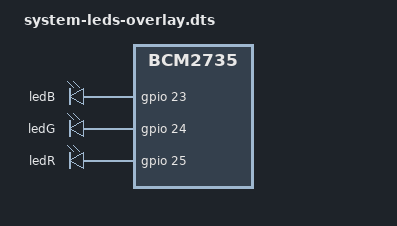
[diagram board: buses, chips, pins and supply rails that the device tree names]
/dts-v1/;
/plugin/;

/ {

  compatible = "brcm,bcm2735";

	fragment@0 {
		target = <&gpio>;
		__overlay__ {
			system_leds_pins: system_leds_pins {
			  brcm,pins = <23 24 25>;
			  brcm,function = <1 1 1>; // 0 = input, 1 = output
			  brcm,pull = <0 0 0>; // 0 = none, 1 = pull down, 2 = pull up
		  };
	  };
  };

	fragment@1 {
		target-path = "/";
		__overlay__ {
			system_leds: system_leds {
			  compatible = "gpio-leds";
			  pinctrl-names = "default";
			  pinctrl-0 = <&system_leds_pins>;
			  status = "okay";

			  ledR: ledR {
		      label = "ledB";
					gpios = <&gpio 23 0>;
			    linux,default-trigger = "none";
				};

        ledG: ledG {
		      label = "ledG";
					gpios = <&gpio 24 0>;
			    linux,default-trigger = "none";
				};

        ledB: ledB {
		      label = "ledR";
				  gpios = <&gpio 25 0>;
			    linux,default-trigger = "none";
				};
			};
		};
	};
};
